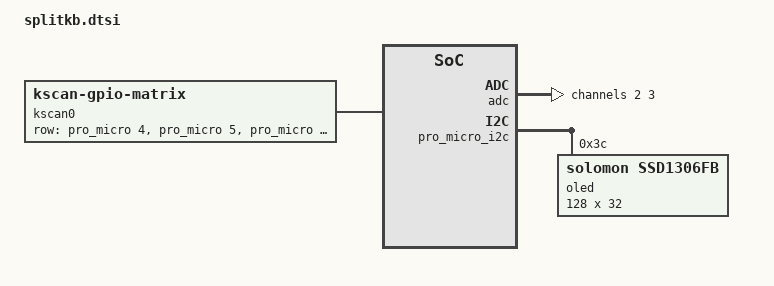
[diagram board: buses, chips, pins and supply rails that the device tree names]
#include <zephyr/dt-bindings/input/input-event-codes.h>
#include <zephyr/dt-bindings/adc/nrf-saadc-v2.h>
#include "splitkb-common.dtsi"   // transform, splits, listeners, physical-layout

/*
 * Parte das METADES (splitkb_left / splitkb_right). O que e igual aos dois
 * lados E ao dongle esta em splitkb-common.dtsi. Aqui fica so o que e de
 * teclado-metade: a matriz de teclas, o ADC do joystick local e a OLED.
 *
 * PINAGEM (igual nos dois lados):
 *   Linhas (4):  D4, D5, D6, D7      -> pro_micro 4,5,6,7  (entradas, pull-down)
 *   Colunas (6): D8, D9, D10, D16, D18, D21 (saidas)   [reversas no lado direito]
 *   OLED I2C:    pro_micro_i2c = D2 (SDA) / D3 (SCL)
 *   Joystick:    X = D19 (AIN0),  Y = D20 (AIN5)
 *   Livres:      D0, D1, D14, D15
 *
 * Diodos: col2row (catodo da tecla apontando para a LINHA).
 */

/ {
    chosen {
        zephyr,display = &oled;
    };

    kscan0: kscan {
        compatible = "zmk,kscan-gpio-matrix";
        wakeup-source;
        diode-direction = "col2row";
        row-gpios
            = <&pro_micro 4 (GPIO_ACTIVE_HIGH | GPIO_PULL_DOWN)>
            , <&pro_micro 5 (GPIO_ACTIVE_HIGH | GPIO_PULL_DOWN)>
            , <&pro_micro 6 (GPIO_ACTIVE_HIGH | GPIO_PULL_DOWN)>
            , <&pro_micro 7 (GPIO_ACTIVE_HIGH | GPIO_PULL_DOWN)>
            ;
        // col-gpios definidas em splitkb_left.overlay / splitkb_right.overlay
    };
};

/*
 * ADC: canais dos eixos do joystick. Presentes nos dois lados.
 *   Canal 2 = X = AIN0 (P0.02 / D19),  Canal 3 = Y = AIN5 (P0.29 / D20).
 *
 * POR QUE 2 e 3 (e NAO 0 e 1): o driver de bateria do ZMK
 * (zmk,battery-nrf-vddh) usa o CANAL 0 fixo -- `.channels = BIT(0)` com
 * input VDDHDIV5. Com o joystick no canal 0, os dois reconfiguravam o mesmo
 * canal e o joystick (que amostra a 100Hz) ganhava; a bateria acabava lendo
 * a tensao do eixo X (~1.66V) e virava 0%. Deixando o canal 0 livre, os dois
 * funcionam.
 *
 * O indice do canal e independente do pino AIN porque
 * CONFIG_ANALOG_INPUT_USE_DTS_ADC_CH_CFG=y faz o driver respeitar o
 * zephyr,input-positive daqui.
 */
&adc {
    status = "okay";
    #address-cells = <1>;
    #size-cells = <0>;

    channel@2 {
        reg = <2>;
        zephyr,gain = "ADC_GAIN_1_6";
        zephyr,reference = "ADC_REF_INTERNAL";
        zephyr,acquisition-time = <ADC_ACQ_TIME(ADC_ACQ_TIME_MICROSECONDS, 10)>;
        zephyr,input-positive = <NRF_SAADC_AIN0>;
        zephyr,resolution = <12>;
    };

    channel@3 {
        reg = <3>;
        zephyr,gain = "ADC_GAIN_1_6";
        zephyr,reference = "ADC_REF_INTERNAL";
        zephyr,acquisition-time = <ADC_ACQ_TIME(ADC_ACQ_TIME_MICROSECONDS, 10)>;
        zephyr,input-positive = <NRF_SAADC_AIN5>;
        zephyr,resolution = <12>;
    };
};

/* OLED SSD1306 no barramento I2C do pro_micro (D2 SDA / D3 SCL). */
&pro_micro_i2c {
    status = "okay";

    oled: ssd1306@3c {
        compatible = "solomon,ssd1306fb";
        reg = <0x3c>;
        width = <128>;
        height = <32>;          /* Se sua OLED for 0.96" 128x64, mude p/ 64 e multiplex p/ 63 */
        segment-offset = <0>;
        page-offset = <0>;
        display-offset = <0>;
        multiplex-ratio = <31>; /* 31 p/ 128x32 ; 63 p/ 128x64 */
        segment-remap;
        com-invdir;
        com-sequential;
        prechargep = <0x22>;
    };
};
